# MSPM0G110X register map
Vendor: Texas Instruments; File version: This preliminary header file does not have a version number - build date: 2023-02-21 16:25:48
CPU: CM0 r0p1, little endian, MPU, no FPU, 3 interrupt priority bits
Registers are 32-bit, read-write, reset 0x0 unless marked. A register's access mark holds for its fields unless they carry their own. Offsets are from the block's base; [hi:lo] are bit positions; {n}, {i} and the like mark numbered series; <NAME> marks a mode.

## I2C0 (part 1 of 2) — PERIPHERALREGION
Base 0x400F0000
Same registers: I2C1 0x400F2000
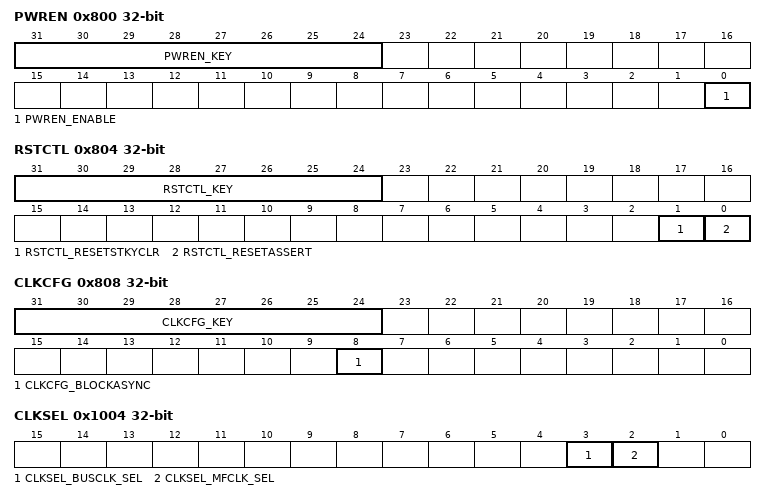
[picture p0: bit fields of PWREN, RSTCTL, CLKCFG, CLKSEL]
0x800 PWREN — Power enable
  [31:24] PWREN_KEY wo — KEY to allow Power State Change
    38=PWREN_KEY_UNLOCK_W (_TO_UNLOCK_W_)
  [0] PWREN_ENABLE — Enable the power
    0=PWREN_ENABLE_DISABLE (DISABLE); 1=PWREN_ENABLE_ENABLE (ENABLE)
0x804 RSTCTL wo — Reset Control
  [31:24] RSTCTL_KEY — Unlock key
    177=RSTCTL_KEY_UNLOCK_W (_TO_UNLOCK_W_)
  [1] RSTCTL_RESETSTKYCLR — Clear the RESETSTKY bit in the STAT register
    0=RSTCTL_RESETSTKYCLR_NOP (NOP); 1=RSTCTL_RESETSTKYCLR_CLR (CLR)
  [0] RSTCTL_RESETASSERT — Assert reset to the peripheral
    0=RSTCTL_RESETASSERT_NOP (NOP); 1=RSTCTL_RESETASSERT_ASSERT (ASSERT)
0x808 CLKCFG — Peripheral Clock Configuration Register
  [31:24] CLKCFG_KEY wo — KEY to Allow State Change -- 0xA9
    169=CLKCFG_KEY_UNLOCK (_UNLOCK_W_)
  [8] CLKCFG_BLOCKASYNC — Async Clock Request is blocked from starting SYSOSC or forcing bus clock to 32MHz
    0=CLKCFG_BLOCKASYNC_DISABLE (DISABLE); 1=CLKCFG_BLOCKASYNC_ENABLE (ENABLE)
0x814 STAT ro — Status Register
  [16] STAT_RESETSTKY — This bit indicates, if the peripheral was reset, since this bit was cleared by RESETSTKYCLR in the RSTCTL register
    0=STAT_RESETSTKY_NORES (NORES); 1=STAT_RESETSTKY_RESET (RESET)
0x1000 CLKDIV — Clock Divider
  [2:0] CLKDIV_RATIO — Selects divide ratio of module clock
    {v}=CLKDIV_RATIO_DIV_BY_{v+1} (DIV_BY_{v+1}) (v=0..7)
0x1004 CLKSEL — Clock Select for Ultra Low Power peripherals
  [3] CLKSEL_BUSCLK_SEL — Selects BUSCLK as clock source if enabled
    0=CLKSEL_BUSCLK_SEL_DISABLE (DISABLE); 1=CLKSEL_BUSCLK_SEL_ENABLE (ENABLE)
  [2] CLKSEL_MFCLK_SEL — Selects MFCLK as clock source if enabled
    0=CLKSEL_MFCLK_SEL_DISABLE (DISABLE); 1=CLKSEL_MFCLK_SEL_ENABLE (ENABLE)
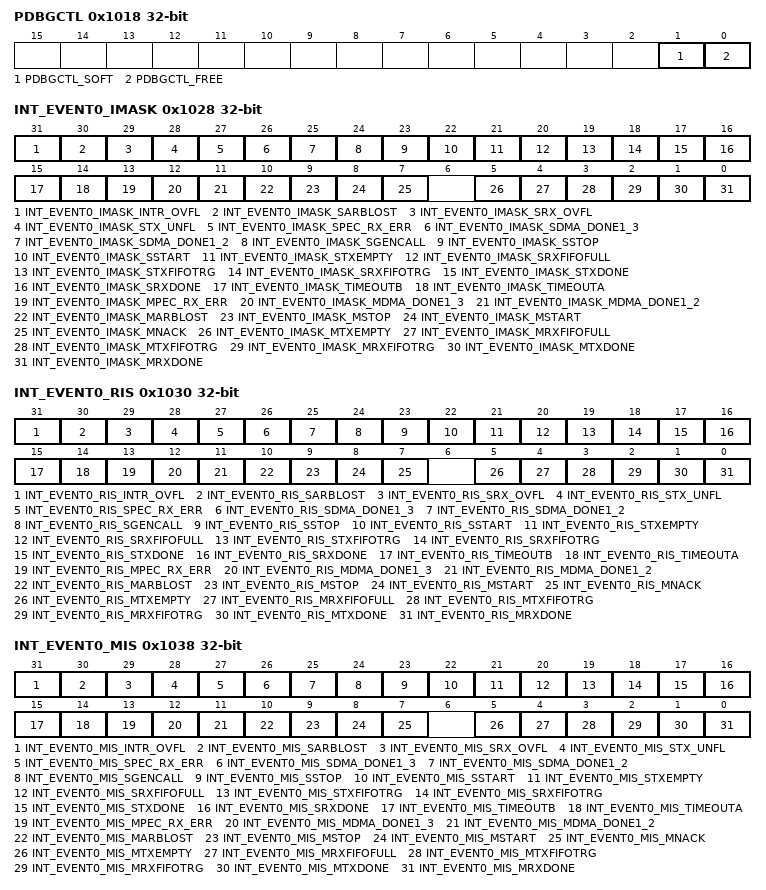
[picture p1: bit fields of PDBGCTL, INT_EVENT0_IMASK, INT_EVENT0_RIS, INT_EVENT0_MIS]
0x1018 PDBGCTL — Peripheral Debug Control
  [1] PDBGCTL_SOFT — Soft halt boundary control. This function is only available, if [FREE] is set to 'STOP'
    0=PDBGCTL_SOFT_IMMEDIATE (IMMEDIATE); 1=PDBGCTL_SOFT_DELAYED (DELAYED)
  [0] PDBGCTL_FREE — Free run control
    0=PDBGCTL_FREE_STOP (STOP); 1=PDBGCTL_FREE_RUN (RUN)
0x1020 INT_EVENT0_IIDX ro — Interrupt index
  [7:0] INT_EVENT0_IIDX_STAT — I2C Module Interrupt Vector Value. This register provides the highes priority interrupt index. A read clears the corresponding interrupt flag in RIS and MISC. 15h-1Fh = Reserved
    0=INT_EVENT0_IIDX_STAT_NO_INTR (NO_INTR); 1=INT_EVENT0_IIDX_STAT_MRXDONEFG (MRXDONEFG); 2=INT_EVENT0_IIDX_STAT_MTXDONEFG (MTXDONEFG); 3=INT_EVENT0_IIDX_STAT_MRXFIFOTRG (MRXFIFOTRG); 4=INT_EVENT0_IIDX_STAT_MTXFIFOTRG (MTXFIFOTRG); 5=INT_EVENT0_IIDX_STAT_MRXFIFOFULL (MRXFIFOFULL); 6=INT_EVENT0_IIDX_STAT_MTX_EMPTY (MTX_EMPTY); 8=INT_EVENT0_IIDX_STAT_MNACKFG (MNACKFG); 9=INT_EVENT0_IIDX_STAT_MSTARTFG (MSTARTFG); 10=INT_EVENT0_IIDX_STAT_MSTOPFG (MSTOPFG); 11=INT_EVENT0_IIDX_STAT_MARBLOSTFG (MARBLOSTFG); 12=INT_EVENT0_IIDX_STAT_MDMA_DONE1_CH2 (MDMA_DONE1_CH2); 13=INT_EVENT0_IIDX_STAT_MDMA_DONE1_CH3 (MDMA_DONE1_CH3); 14=INT_EVENT0_IIDX_STAT_MPEC_RX_ERR (MPEC_RX_ERR); 15=INT_EVENT0_IIDX_STAT_TIMEOUTA (TIMEOUTA); 16=INT_EVENT0_IIDX_STAT_TIMEOUTB (TIMEOUTB); 17=INT_EVENT0_IIDX_STAT_SRXDONEFG (SRXDONEFG); 18=INT_EVENT0_IIDX_STAT_STXDONEFG (STXDONEFG); 19=INT_EVENT0_IIDX_STAT_SRXFIFOTRG (SRXFIFOTRG); 20=INT_EVENT0_IIDX_STAT_STXFIFOTRG (STXFIFOTRG); 21=INT_EVENT0_IIDX_STAT_SRXFIFOFULL (SRXFIFOFULL); 22=INT_EVENT0_IIDX_STAT_STXEMPTY (STXEMPTY); 23=INT_EVENT0_IIDX_STAT_SSTARTFG (SSTARTFG); 24=INT_EVENT0_IIDX_STAT_SSTOPFG (SSTOPFG); 25=INT_EVENT0_IIDX_STAT_SGENCALL (SGENCALL); 26=INT_EVENT0_IIDX_STAT_SDMA_DONE1_CH2 (SDMA_DONE1_CH2); 27=INT_EVENT0_IIDX_STAT_SDMA_DONE1_CH3 (SDMA_DONE1_CH3); 28=INT_EVENT0_IIDX_STAT_SPEC_RX_ERR (SPEC_RX_ERR); 29=INT_EVENT0_IIDX_STAT_STX_UNFL (STX_UNFL); 30=INT_EVENT0_IIDX_STAT_SRX_OVFL (SRX_OVFL); 31=INT_EVENT0_IIDX_STAT_SARBLOST (SARBLOST); 32=INT_EVENT0_IIDX_STAT_INTR_OVFL (INTR_OVFL)
0x1028 INT_EVENT0_IMASK — Interrupt mask
  [31] INT_EVENT0_IMASK_INTR_OVFL — Interrupt Overflow Interrupt Mask
    0=INT_EVENT0_IMASK_INTR_OVFL_CLR (CLR); 1=INT_EVENT0_IMASK_INTR_OVFL_SET (SET)
  [30] INT_EVENT0_IMASK_SARBLOST — Slave Arbitration Lost
    0=INT_EVENT0_IMASK_SARBLOST_CLR (CLR); 1=INT_EVENT0_IMASK_SARBLOST_SET (SET)
  [29] INT_EVENT0_IMASK_SRX_OVFL — Slave RX FIFO overflow
    0=INT_EVENT0_IMASK_SRX_OVFL_CLR (CLR); 1=INT_EVENT0_IMASK_SRX_OVFL_SET (SET)
  [28] INT_EVENT0_IMASK_STX_UNFL — Slave TX FIFO underflow
    0=INT_EVENT0_IMASK_STX_UNFL_CLR (CLR); 1=INT_EVENT0_IMASK_STX_UNFL_SET (SET)
  [27] INT_EVENT0_IMASK_SPEC_RX_ERR — Slave RX Pec Error Interrupt
    0=INT_EVENT0_IMASK_SPEC_RX_ERR_CLR (CLR); 1=INT_EVENT0_IMASK_SPEC_RX_ERR_SET (SET)
  [26] INT_EVENT0_IMASK_SDMA_DONE1_3 — Slave DMA Done 1 on Event Channel 3
    0=INT_EVENT0_IMASK_SDMA_DONE1_3_CLR (CLR); 1=INT_EVENT0_IMASK_SDMA_DONE1_3_SET (SET)
  [25] INT_EVENT0_IMASK_SDMA_DONE1_2 — Slave DMA Done 1 on Event Channel 2
    0=INT_EVENT0_IMASK_SDMA_DONE1_2_CLR (CLR); 1=INT_EVENT0_IMASK_SDMA_DONE1_2_SET (SET)
  [24] INT_EVENT0_IMASK_SGENCALL — General Call Interrupt
    0=INT_EVENT0_IMASK_SGENCALL_CLR (CLR); 1=INT_EVENT0_IMASK_SGENCALL_SET (SET)
  [23] INT_EVENT0_IMASK_SSTOP — Stop Condition Interrupt
    0=INT_EVENT0_IMASK_SSTOP_CLR (CLR); 1=INT_EVENT0_IMASK_SSTOP_SET (SET)
  [22] INT_EVENT0_IMASK_SSTART — Start Condition Interrupt
    0=INT_EVENT0_IMASK_SSTART_CLR (CLR); 1=INT_EVENT0_IMASK_SSTART_SET (SET)
  [21] INT_EVENT0_IMASK_STXEMPTY — Slave Transmit FIFO Empty interrupt mask. This interrupt is set if all data in the Transmit FIFO have been shifted out and the transmit goes into idle mode.
    0=INT_EVENT0_IMASK_STXEMPTY_CLR (CLR); 1=INT_EVENT0_IMASK_STXEMPTY_SET (SET)
  [20] INT_EVENT0_IMASK_SRXFIFOFULL — RXFIFO full event. This interrupt is set if an Slave RX FIFO is full.
    0=INT_EVENT0_IMASK_SRXFIFOFULL_CLR (CLR); 1=INT_EVENT0_IMASK_SRXFIFOFULL_SET (SET)
  [19] INT_EVENT0_IMASK_STXFIFOTRG — Slave Transmit FIFO Trigger
    0=INT_EVENT0_IMASK_STXFIFOTRG_CLR (CLR); 1=INT_EVENT0_IMASK_STXFIFOTRG_SET (SET)
  [18] INT_EVENT0_IMASK_SRXFIFOTRG — Slave Receive FIFO Trigger
    0=INT_EVENT0_IMASK_SRXFIFOTRG_CLR (CLR); 1=INT_EVENT0_IMASK_SRXFIFOTRG_SET (SET)
  [17] INT_EVENT0_IMASK_STXDONE — Slave Transmit Transaction completed Interrupt
    0=INT_EVENT0_IMASK_STXDONE_CLR (CLR); 1=INT_EVENT0_IMASK_STXDONE_SET (SET)
  [16] INT_EVENT0_IMASK_SRXDONE — Slave Receive Data Interrupt Signals that a byte has been received
    0=INT_EVENT0_IMASK_SRXDONE_CLR (CLR); 1=INT_EVENT0_IMASK_SRXDONE_SET (SET)
  [15] INT_EVENT0_IMASK_TIMEOUTB — Timeout B Interrupt
    0=INT_EVENT0_IMASK_TIMEOUTB_CLR (CLR); 1=INT_EVENT0_IMASK_TIMEOUTB_SET (SET)
  [14] INT_EVENT0_IMASK_TIMEOUTA — Timeout A Interrupt
    0=INT_EVENT0_IMASK_TIMEOUTA_CLR (CLR); 1=INT_EVENT0_IMASK_TIMEOUTA_SET (SET)
  [13] INT_EVENT0_IMASK_MPEC_RX_ERR — Master RX Pec Error Interrupt
    0=INT_EVENT0_IMASK_MPEC_RX_ERR_CLR (CLR); 1=INT_EVENT0_IMASK_MPEC_RX_ERR_SET (SET)
  [12] INT_EVENT0_IMASK_MDMA_DONE1_3 — DMA Done 1 on Event Channel 3
    0=INT_EVENT0_IMASK_MDMA_DONE1_3_CLR (CLR); 1=INT_EVENT0_IMASK_MDMA_DONE1_3_SET (SET)
  [11] INT_EVENT0_IMASK_MDMA_DONE1_2 — DMA Done 1 on Event Channel 2
    0=INT_EVENT0_IMASK_MDMA_DONE1_2_CLR (CLR); 1=INT_EVENT0_IMASK_MDMA_DONE1_2_SET (SET)
  [10] INT_EVENT0_IMASK_MARBLOST — Arbitration Lost Interrupt
    0=INT_EVENT0_IMASK_MARBLOST_CLR (CLR); 1=INT_EVENT0_IMASK_MARBLOST_SET (SET)
  [9] INT_EVENT0_IMASK_MSTOP — STOP Detection Interrupt
    0=INT_EVENT0_IMASK_MSTOP_CLR (CLR); 1=INT_EVENT0_IMASK_MSTOP_SET (SET)
  [8] INT_EVENT0_IMASK_MSTART — START Detection Interrupt
    0=INT_EVENT0_IMASK_MSTART_CLR (CLR); 1=INT_EVENT0_IMASK_MSTART_SET (SET)
  [7] INT_EVENT0_IMASK_MNACK — Address/Data NACK Interrupt
    0=INT_EVENT0_IMASK_MNACK_CLR (CLR); 1=INT_EVENT0_IMASK_MNACK_SET (SET)
  [5] INT_EVENT0_IMASK_MTXEMPTY — Transmit FIFO Empty interrupt mask. This interrupt is set if all data in the Transmit FIFO have been shifted out and the transmit goes into idle mode.
    0=INT_EVENT0_IMASK_MTXEMPTY_CLR (CLR); 1=INT_EVENT0_IMASK_MTXEMPTY_SET (SET)
  [4] INT_EVENT0_IMASK_MRXFIFOFULL — RXFIFO full event. This interrupt is set if an RX FIFO is full.
    0=INT_EVENT0_IMASK_MRXFIFOFULL_CLR (CLR); 1=INT_EVENT0_IMASK_MRXFIFOFULL_SET (SET)
  [3] INT_EVENT0_IMASK_MTXFIFOTRG — Master Transmit FIFO Trigger Trigger when Transmit FIFO contains <= defined bytes
    0=INT_EVENT0_IMASK_MTXFIFOTRG_CLR (CLR); 1=INT_EVENT0_IMASK_MTXFIFOTRG_SET (SET)
  [2] INT_EVENT0_IMASK_MRXFIFOTRG — Master Receive FIFO Trigger Trigger when RX FIFO contains >= defined bytes
    0=INT_EVENT0_IMASK_MRXFIFOTRG_CLR (CLR); 1=INT_EVENT0_IMASK_MRXFIFOTRG_SET (SET)
  [1] INT_EVENT0_IMASK_MTXDONE — Master Transmit Transaction completed Interrupt
    0=INT_EVENT0_IMASK_MTXDONE_CLR (CLR); 1=INT_EVENT0_IMASK_MTXDONE_SET (SET)
  [0] INT_EVENT0_IMASK_MRXDONE — Master Receive Transaction completed Interrupt
    0=INT_EVENT0_IMASK_MRXDONE_CLR (CLR); 1=INT_EVENT0_IMASK_MRXDONE_SET (SET)
0x1030 INT_EVENT0_RIS ro — Raw interrupt status
  [31] INT_EVENT0_RIS_INTR_OVFL — Interrupt overflow interrupt It is set when SSTART or SSTOP interrupts overflow i.e. occur twice without being serviced
    0=INT_EVENT0_RIS_INTR_OVFL_CLR (CLR); 1=INT_EVENT0_RIS_INTR_OVFL_SET (SET)
  [30] INT_EVENT0_RIS_SARBLOST — Slave Arbitration Lost
    0=INT_EVENT0_RIS_SARBLOST_CLR (CLR); 1=INT_EVENT0_RIS_SARBLOST_SET (SET)
  [29] INT_EVENT0_RIS_SRX_OVFL — Slave RX FIFO overflow
    0=INT_EVENT0_RIS_SRX_OVFL_CLR (CLR); 1=INT_EVENT0_RIS_SRX_OVFL_SET (SET)
  [28] INT_EVENT0_RIS_STX_UNFL — Slave TX FIFO underflow
    0=INT_EVENT0_RIS_STX_UNFL_CLR (CLR); 1=INT_EVENT0_RIS_STX_UNFL_SET (SET)
  [27] INT_EVENT0_RIS_SPEC_RX_ERR — Slave RX Pec Error Interrupt
    0=INT_EVENT0_RIS_SPEC_RX_ERR_CLR (CLR); 1=INT_EVENT0_RIS_SPEC_RX_ERR_SET (SET)
  [26] INT_EVENT0_RIS_SDMA_DONE1_3 — DMA Done 1 on Event Channel 3
    0=INT_EVENT0_RIS_SDMA_DONE1_3_CLR (CLR); 1=INT_EVENT0_RIS_SDMA_DONE1_3_SET (SET)
  [25] INT_EVENT0_RIS_SDMA_DONE1_2 — DMA Done 1 on Event Channel 2
    0=INT_EVENT0_RIS_SDMA_DONE1_2_CLR (CLR); 1=INT_EVENT0_RIS_SDMA_DONE1_2_SET (SET)
  [24] INT_EVENT0_RIS_SGENCALL — General Call Interrupt
    0=INT_EVENT0_RIS_SGENCALL_CLR (CLR); 1=INT_EVENT0_RIS_SGENCALL_SET (SET)
  [23] INT_EVENT0_RIS_SSTOP — Stop Condition Interrupt
    0=INT_EVENT0_RIS_SSTOP_CLR (CLR); 1=INT_EVENT0_RIS_SSTOP_SET (SET)
  [22] INT_EVENT0_RIS_SSTART — Start Condition Interrupt
    0=INT_EVENT0_RIS_SSTART_CLR (CLR); 1=INT_EVENT0_RIS_SSTART_SET (SET)
  [21] INT_EVENT0_RIS_STXEMPTY — Transmit FIFO Empty interrupt mask. This interrupt is set if all data in the Transmit FIFO have been shifted out and the transmit goes into idle mode.
    0=INT_EVENT0_RIS_STXEMPTY_CLR (CLR); 1=INT_EVENT0_RIS_STXEMPTY_SET (SET)
  [20] INT_EVENT0_RIS_SRXFIFOFULL — RXFIFO full event. This interrupt is set if an RX FIFO is full.
    0=INT_EVENT0_RIS_SRXFIFOFULL_CLR (CLR); 1=INT_EVENT0_RIS_SRXFIFOFULL_SET (SET)
  [19] INT_EVENT0_RIS_STXFIFOTRG — Slave Transmit FIFO Trigger
    0=INT_EVENT0_RIS_STXFIFOTRG_CLR (CLR); 1=INT_EVENT0_RIS_STXFIFOTRG_SET (SET)
  [18] INT_EVENT0_RIS_SRXFIFOTRG — Slave Receive FIFO Trigger
    0=INT_EVENT0_RIS_SRXFIFOTRG_CLR (CLR); 1=INT_EVENT0_RIS_SRXFIFOTRG_SET (SET)
  [17] INT_EVENT0_RIS_STXDONE — Slave Transmit Transaction completed Interrupt
    0=INT_EVENT0_RIS_STXDONE_CLR (CLR); 1=INT_EVENT0_RIS_STXDONE_SET (SET)
  [16] INT_EVENT0_RIS_SRXDONE — Slave Receive Data Interrupt Signals that a byte has been received
    0=INT_EVENT0_RIS_SRXDONE_CLR (CLR); 1=INT_EVENT0_RIS_SRXDONE_SET (SET)
  [15] INT_EVENT0_RIS_TIMEOUTB — Timeout B Interrupt
    0=INT_EVENT0_RIS_TIMEOUTB_CLR (CLR); 1=INT_EVENT0_RIS_TIMEOUTB_SET (SET)
  [14] INT_EVENT0_RIS_TIMEOUTA — Timeout A Interrupt
    0=INT_EVENT0_RIS_TIMEOUTA_CLR (CLR); 1=INT_EVENT0_RIS_TIMEOUTA_SET (SET)
  [13] INT_EVENT0_RIS_MPEC_RX_ERR — Master RX Pec Error Interrupt
    0=INT_EVENT0_RIS_MPEC_RX_ERR_CLR (CLR); 1=INT_EVENT0_RIS_MPEC_RX_ERR_SET (SET)
  [12] INT_EVENT0_RIS_MDMA_DONE1_3 — DMA Done 1 on Event Channel 3
    0=INT_EVENT0_RIS_MDMA_DONE1_3_CLR (CLR); 1=INT_EVENT0_RIS_MDMA_DONE1_3_SET (SET)
  [11] INT_EVENT0_RIS_MDMA_DONE1_2 — DMA Done 1 on Event Channel 2
    0=INT_EVENT0_RIS_MDMA_DONE1_2_CLR (CLR); 1=INT_EVENT0_RIS_MDMA_DONE1_2_SET (SET)
  [10] INT_EVENT0_RIS_MARBLOST — Arbitration Lost Interrupt
    0=INT_EVENT0_RIS_MARBLOST_CLR (CLR); 1=INT_EVENT0_RIS_MARBLOST_SET (SET)
  [9] INT_EVENT0_RIS_MSTOP — STOP Detection Interrupt
    0=INT_EVENT0_RIS_MSTOP_CLR (CLR); 1=INT_EVENT0_RIS_MSTOP_SET (SET)
  [8] INT_EVENT0_RIS_MSTART — START Detection Interrupt
    0=INT_EVENT0_RIS_MSTART_CLR (CLR); 1=INT_EVENT0_RIS_MSTART_SET (SET)
  [7] INT_EVENT0_RIS_MNACK — Address/Data NACK Interrupt
    0=INT_EVENT0_RIS_MNACK_CLR (CLR); 1=INT_EVENT0_RIS_MNACK_SET (SET)
  [5] INT_EVENT0_RIS_MTXEMPTY — Transmit FIFO Empty interrupt mask. This interrupt is set if all data in the Transmit FIFO have been shifted out and the transmit goes into idle mode.
    0=INT_EVENT0_RIS_MTXEMPTY_CLR (CLR); 1=INT_EVENT0_RIS_MTXEMPTY_SET (SET)
  [4] INT_EVENT0_RIS_MRXFIFOFULL — RXFIFO full event. This interrupt is set if an RX FIFO is full.
    0=INT_EVENT0_RIS_MRXFIFOFULL_CLR (CLR); 1=INT_EVENT0_RIS_MRXFIFOFULL_SET (SET)
  [3] INT_EVENT0_RIS_MTXFIFOTRG — Master Transmit FIFO Trigger Trigger when Transmit FIFO contains <= defined bytes
    0=INT_EVENT0_RIS_MTXFIFOTRG_CLR (CLR); 1=INT_EVENT0_RIS_MTXFIFOTRG_SET (SET)
  [2] INT_EVENT0_RIS_MRXFIFOTRG — Master Receive FIFO Trigger Trigger when RX FIFO contains >= defined bytes
    0=INT_EVENT0_RIS_MRXFIFOTRG_CLR (CLR); 1=INT_EVENT0_RIS_MRXFIFOTRG_SET (SET)
  [1] INT_EVENT0_RIS_MTXDONE — Master Transmit Transaction completed Interrupt
    0=INT_EVENT0_RIS_MTXDONE_CLR (CLR); 1=INT_EVENT0_RIS_MTXDONE_SET (SET)
  [0] INT_EVENT0_RIS_MRXDONE — Master Receive Transaction completed Interrupt
    0=INT_EVENT0_RIS_MRXDONE_CLR (CLR); 1=INT_EVENT0_RIS_MRXDONE_SET (SET)
0x1038 INT_EVENT0_MIS ro — Masked interrupt status
  [31] INT_EVENT0_MIS_INTR_OVFL — Interrupt overflow
    0=INT_EVENT0_MIS_INTR_OVFL_CLR (CLR); 1=INT_EVENT0_MIS_INTR_OVFL_SET (SET)
  [30] INT_EVENT0_MIS_SARBLOST — Slave Arbitration Lost
    0=INT_EVENT0_MIS_SARBLOST_CLR (CLR); 1=INT_EVENT0_MIS_SARBLOST_SET (SET)
  [29] INT_EVENT0_MIS_SRX_OVFL — Slave RX FIFO overflow
    0=INT_EVENT0_MIS_SRX_OVFL_CLR (CLR); 1=INT_EVENT0_MIS_SRX_OVFL_SET (SET)
  [28] INT_EVENT0_MIS_STX_UNFL — Slave TX FIFO underflow
    0=INT_EVENT0_MIS_STX_UNFL_CLR (CLR); 1=INT_EVENT0_MIS_STX_UNFL_SET (SET)
  [27] INT_EVENT0_MIS_SPEC_RX_ERR — Slave RX Pec Error Interrupt
    0=INT_EVENT0_MIS_SPEC_RX_ERR_CLR (CLR); 1=INT_EVENT0_MIS_SPEC_RX_ERR_SET (SET)
  [26] INT_EVENT0_MIS_SDMA_DONE1_3 — DMA Done 1 on Event Channel 3
    0=INT_EVENT0_MIS_SDMA_DONE1_3_CLR (CLR); 1=INT_EVENT0_MIS_SDMA_DONE1_3_SET (SET)
  [25] INT_EVENT0_MIS_SDMA_DONE1_2 — DMA Done 1 on Event Channel 2
    0=INT_EVENT0_MIS_SDMA_DONE1_2_CLR (CLR); 1=INT_EVENT0_MIS_SDMA_DONE1_2_SET (SET)
  [24] INT_EVENT0_MIS_SGENCALL — General Call Interrupt
    0=INT_EVENT0_MIS_SGENCALL_CLR (CLR); 1=INT_EVENT0_MIS_SGENCALL_SET (SET)
  [23] INT_EVENT0_MIS_SSTOP — Slave STOP Detection Interrupt
    0=INT_EVENT0_MIS_SSTOP_CLR (CLR); 1=INT_EVENT0_MIS_SSTOP_SET (SET)
  [22] INT_EVENT0_MIS_SSTART — Slave START Detection Interrupt
    0=INT_EVENT0_MIS_SSTART_CLR (CLR); 1=INT_EVENT0_MIS_SSTART_SET (SET)
  [21] INT_EVENT0_MIS_STXEMPTY — Transmit FIFO Empty interrupt mask. This interrupt is set if all data in the Transmit FIFO have been shifted out and the transmit goes into idle mode.
    0=INT_EVENT0_MIS_STXEMPTY_CLR (CLR); 1=INT_EVENT0_MIS_STXEMPTY_SET (SET)
  [20] INT_EVENT0_MIS_SRXFIFOFULL — RXFIFO full event. This interrupt is set if an RX FIFO is full.
    0=INT_EVENT0_MIS_SRXFIFOFULL_CLR (CLR); 1=INT_EVENT0_MIS_SRXFIFOFULL_SET (SET)
  [19] INT_EVENT0_MIS_STXFIFOTRG — Slave Transmit FIFO Trigger
    0=INT_EVENT0_MIS_STXFIFOTRG_CLR (CLR); 1=INT_EVENT0_MIS_STXFIFOTRG_SET (SET)
  [18] INT_EVENT0_MIS_SRXFIFOTRG — Slave Receive FIFO Trigger
    0=INT_EVENT0_MIS_SRXFIFOTRG_CLR (CLR); 1=INT_EVENT0_MIS_SRXFIFOTRG_SET (SET)
  [17] INT_EVENT0_MIS_STXDONE — Slave Transmit Transaction completed Interrupt
    0=INT_EVENT0_MIS_STXDONE_CLR (CLR); 1=INT_EVENT0_MIS_STXDONE_SET (SET)
  [16] INT_EVENT0_MIS_SRXDONE — Slave Receive Data Interrupt Signals that a byte has been received
    0=INT_EVENT0_MIS_SRXDONE_CLR (CLR); 1=INT_EVENT0_MIS_SRXDONE_SET (SET)
  [15] INT_EVENT0_MIS_TIMEOUTB — Timeout B Interrupt
    0=INT_EVENT0_MIS_TIMEOUTB_CLR (CLR); 1=INT_EVENT0_MIS_TIMEOUTB_SET (SET)
  [14] INT_EVENT0_MIS_TIMEOUTA — Timeout A Interrupt
    0=INT_EVENT0_MIS_TIMEOUTA_CLR (CLR); 1=INT_EVENT0_MIS_TIMEOUTA_SET (SET)
  [13] INT_EVENT0_MIS_MPEC_RX_ERR — Master RX Pec Error Interrupt
    0=INT_EVENT0_MIS_MPEC_RX_ERR_CLR (CLR); 1=INT_EVENT0_MIS_MPEC_RX_ERR_SET (SET)
  [12] INT_EVENT0_MIS_MDMA_DONE1_3 — DMA Done 1 on Event Channel 3
    0=INT_EVENT0_MIS_MDMA_DONE1_3_CLR (CLR); 1=INT_EVENT0_MIS_MDMA_DONE1_3_SET (SET)
  [11] INT_EVENT0_MIS_MDMA_DONE1_2 — DMA Done 1 on Event Channel 2
    0=INT_EVENT0_MIS_MDMA_DONE1_2_CLR (CLR); 1=INT_EVENT0_MIS_MDMA_DONE1_2_SET (SET)
  [10] INT_EVENT0_MIS_MARBLOST — Arbitration Lost Interrupt
    0=INT_EVENT0_MIS_MARBLOST_CLR (CLR); 1=INT_EVENT0_MIS_MARBLOST_SET (SET)
  [9] INT_EVENT0_MIS_MSTOP — STOP Detection Interrupt
    0=INT_EVENT0_MIS_MSTOP_CLR (CLR); 1=INT_EVENT0_MIS_MSTOP_SET (SET)
  [8] INT_EVENT0_MIS_MSTART — START Detection Interrupt
    0=INT_EVENT0_MIS_MSTART_CLR (CLR); 1=INT_EVENT0_MIS_MSTART_SET (SET)
  [7] INT_EVENT0_MIS_MNACK — Address/Data NACK Interrupt
    0=INT_EVENT0_MIS_MNACK_CLR (CLR); 1=INT_EVENT0_MIS_MNACK_SET (SET)
  [5] INT_EVENT0_MIS_MTXEMPTY — Transmit FIFO Empty interrupt mask. This interrupt is set if all data in the Transmit FIFO have been shifted out and the transmit goes into idle mode.
    0=INT_EVENT0_MIS_MTXEMPTY_CLR (CLR); 1=INT_EVENT0_MIS_MTXEMPTY_SET (SET)
  [4] INT_EVENT0_MIS_MRXFIFOFULL — RXFIFO full event. This interrupt is set if the RX FIFO is full.
    0=INT_EVENT0_MIS_MRXFIFOFULL_CLR (CLR); 1=INT_EVENT0_MIS_MRXFIFOFULL_SET (SET)
  [3] INT_EVENT0_MIS_MTXFIFOTRG — Master Transmit FIFO Trigger Trigger when Transmit FIFO contains <= defined bytes
    0=INT_EVENT0_MIS_MTXFIFOTRG_CLR (CLR); 1=INT_EVENT0_MIS_MTXFIFOTRG_SET (SET)
  [2] INT_EVENT0_MIS_MRXFIFOTRG — Master Receive FIFO Trigger Trigger when RX FIFO contains >= defined bytes
    0=INT_EVENT0_MIS_MRXFIFOTRG_CLR (CLR); 1=INT_EVENT0_MIS_MRXFIFOTRG_SET (SET)
  [1] INT_EVENT0_MIS_MTXDONE — Master Transmit Transaction completed Interrupt
    0=INT_EVENT0_MIS_MTXDONE_CLR (CLR); 1=INT_EVENT0_MIS_MTXDONE_SET (SET)
  [0] INT_EVENT0_MIS_MRXDONE — Master Receive Data Interrupt
    0=INT_EVENT0_MIS_MRXDONE_CLR (CLR); 1=INT_EVENT0_MIS_MRXDONE_SET (SET)
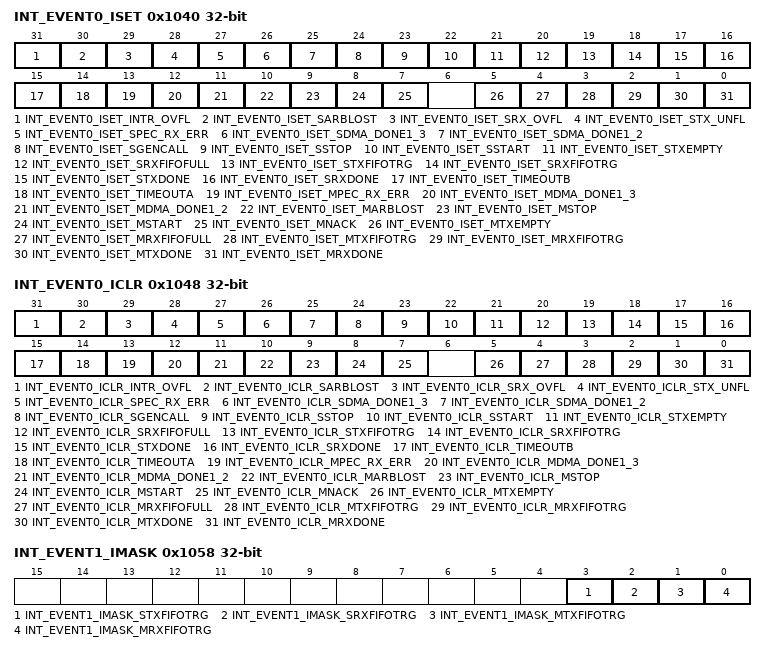
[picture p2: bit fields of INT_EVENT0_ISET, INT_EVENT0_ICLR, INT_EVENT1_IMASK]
0x1040 INT_EVENT0_ISET wo — Interrupt set
  [31] INT_EVENT0_ISET_INTR_OVFL — Interrupt overflow
    0=INT_EVENT0_ISET_INTR_OVFL_NO_EFFECT (NO_EFFECT); 1=INT_EVENT0_ISET_INTR_OVFL_SET (SET)
  [30] INT_EVENT0_ISET_SARBLOST — Slave Arbitration Lost
    0=INT_EVENT0_ISET_SARBLOST_NO_EFFECT (NO_EFFECT); 1=INT_EVENT0_ISET_SARBLOST_SET (SET)
  [29] INT_EVENT0_ISET_SRX_OVFL — Slave RX FIFO overflow
    0=INT_EVENT0_ISET_SRX_OVFL_NO_EFFECT (NO_EFFECT); 1=INT_EVENT0_ISET_SRX_OVFL_SET (SET)
  [28] INT_EVENT0_ISET_STX_UNFL — Slave TX FIFO underflow
    0=INT_EVENT0_ISET_STX_UNFL_NO_EFFECT (NO_EFFECT); 1=INT_EVENT0_ISET_STX_UNFL_SET (SET)
  [27] INT_EVENT0_ISET_SPEC_RX_ERR — Slave RX Pec Error Interrupt
    0=INT_EVENT0_ISET_SPEC_RX_ERR_NO_EFFECT (NO_EFFECT); 1=INT_EVENT0_ISET_SPEC_RX_ERR_SET (SET)
  [26] INT_EVENT0_ISET_SDMA_DONE1_3 — DMA Done 1 on Event Channel 3
    0=INT_EVENT0_ISET_SDMA_DONE1_3_NO_EFFECT (NO_EFFECT); 1=INT_EVENT0_ISET_SDMA_DONE1_3_SET (SET)
  [25] INT_EVENT0_ISET_SDMA_DONE1_2 — DMA Done 1 on Event Channel 2
    0=INT_EVENT0_ISET_SDMA_DONE1_2_NO_EFFECT (NO_EFFECT); 1=INT_EVENT0_ISET_SDMA_DONE1_2_SET (SET)
  [24] INT_EVENT0_ISET_SGENCALL — General Call Interrupt
    0=INT_EVENT0_ISET_SGENCALL_NO_EFFECT (NO_EFFECT); 1=INT_EVENT0_ISET_SGENCALL_SET (SET)
  [23] INT_EVENT0_ISET_SSTOP — Stop Condition Interrupt
    0=INT_EVENT0_ISET_SSTOP_NO_EFFECT (NO_EFFECT); 1=INT_EVENT0_ISET_SSTOP_SET (SET)
  [22] INT_EVENT0_ISET_SSTART — Start Condition Interrupt
    0=INT_EVENT0_ISET_SSTART_NO_EFFECT (NO_EFFECT); 1=INT_EVENT0_ISET_SSTART_SET (SET)
  [21] INT_EVENT0_ISET_STXEMPTY — Transmit FIFO Empty interrupt mask. This interrupt is set if all data in the Transmit FIFO have been shifted out and the transmit goes into idle mode.
    0=INT_EVENT0_ISET_STXEMPTY_NO_EFFECT (NO_EFFECT); 1=INT_EVENT0_ISET_STXEMPTY_SET (SET)
  [20] INT_EVENT0_ISET_SRXFIFOFULL — RXFIFO full event. This interrupt is set if an RX FIFO is full.
    0=INT_EVENT0_ISET_SRXFIFOFULL_NO_EFFECT (NO_EFFECT); 1=INT_EVENT0_ISET_SRXFIFOFULL_SET (SET)
  [19] INT_EVENT0_ISET_STXFIFOTRG — Slave Transmit FIFO Trigger
    0=INT_EVENT0_ISET_STXFIFOTRG_NO_EFFECT (NO_EFFECT); 1=INT_EVENT0_ISET_STXFIFOTRG_SET (SET)
  [18] INT_EVENT0_ISET_SRXFIFOTRG — Slave Receive FIFO Trigger
    0=INT_EVENT0_ISET_SRXFIFOTRG_NO_EFFECT (NO_EFFECT); 1=INT_EVENT0_ISET_SRXFIFOTRG_SET (SET)
  [17] INT_EVENT0_ISET_STXDONE — Slave Transmit Transaction completed Interrupt
    0=INT_EVENT0_ISET_STXDONE_NO_EFFECT (NO_EFFECT); 1=INT_EVENT0_ISET_STXDONE_SET (SET)
  [16] INT_EVENT0_ISET_SRXDONE — Slave Receive Data Interrupt Signals that a byte has been received
    0=INT_EVENT0_ISET_SRXDONE_NO_EFFECT (NO_EFFECT); 1=INT_EVENT0_ISET_SRXDONE_SET (SET)
  [15] INT_EVENT0_ISET_TIMEOUTB — Timeout B Interrupt
    0=INT_EVENT0_ISET_TIMEOUTB_NO_EFFECT (NO_EFFECT); 1=INT_EVENT0_ISET_TIMEOUTB_SET (SET)
  [14] INT_EVENT0_ISET_TIMEOUTA — Timeout A interrupt
    0=INT_EVENT0_ISET_TIMEOUTA_NO_EFFECT (NO_EFFECT); 1=INT_EVENT0_ISET_TIMEOUTA_SET (SET)
  [13] INT_EVENT0_ISET_MPEC_RX_ERR — Master RX Pec Error Interrupt
    0=INT_EVENT0_ISET_MPEC_RX_ERR_NO_EFFECT (NO_EFFECT); 1=INT_EVENT0_ISET_MPEC_RX_ERR_SET (SET)
  [12] INT_EVENT0_ISET_MDMA_DONE1_3 — DMA Done 1 on Event Channel 3
    0=INT_EVENT0_ISET_MDMA_DONE1_3_NO_EFFECT (NO_EFFECT); 1=INT_EVENT0_ISET_MDMA_DONE1_3_SET (SET)
  [11] INT_EVENT0_ISET_MDMA_DONE1_2 — DMA Done 1 on Event Channel 2
    0=INT_EVENT0_ISET_MDMA_DONE1_2_NO_EFFECT (NO_EFFECT); 1=INT_EVENT0_ISET_MDMA_DONE1_2_SET (SET)
  [10] INT_EVENT0_ISET_MARBLOST — Arbitration Lost Interrupt
    0=INT_EVENT0_ISET_MARBLOST_NO_EFFECT (NO_EFFECT); 1=INT_EVENT0_ISET_MARBLOST_SET (SET)
  [9] INT_EVENT0_ISET_MSTOP — STOP Detection Interrupt
    0=INT_EVENT0_ISET_MSTOP_NO_EFFECT (NO_EFFECT); 1=INT_EVENT0_ISET_MSTOP_SET (SET)
  [8] INT_EVENT0_ISET_MSTART — START Detection Interrupt
    0=INT_EVENT0_ISET_MSTART_NO_EFFECT (NO_EFFECT); 1=INT_EVENT0_ISET_MSTART_SET (SET)
  [7] INT_EVENT0_ISET_MNACK — Address/Data NACK Interrupt
    0=INT_EVENT0_ISET_MNACK_NO_EFFECT (NO_EFFECT); 1=INT_EVENT0_ISET_MNACK_SET (SET)
  [5] INT_EVENT0_ISET_MTXEMPTY — Transmit FIFO Empty interrupt mask. This interrupt is set if all data in the Transmit FIFO have been shifted out and the transmit goes into idle mode.
    0=INT_EVENT0_ISET_MTXEMPTY_NO_EFFECT (NO_EFFECT); 1=INT_EVENT0_ISET_MTXEMPTY_SET (SET)
  [4] INT_EVENT0_ISET_MRXFIFOFULL — RXFIFO full event.
    0=INT_EVENT0_ISET_MRXFIFOFULL_NO_EFFECT (NO_EFFECT); 1=INT_EVENT0_ISET_MRXFIFOFULL_SET (SET)
  [3] INT_EVENT0_ISET_MTXFIFOTRG — Master Transmit FIFO Trigger Trigger when Transmit FIFO contains <= defined bytes
    0=INT_EVENT0_ISET_MTXFIFOTRG_NO_EFFECT (NO_EFFECT); 1=INT_EVENT0_ISET_MTXFIFOTRG_SET (SET)
  [2] INT_EVENT0_ISET_MRXFIFOTRG — Master Receive FIFO Trigger Trigger when RX FIFO contains >= defined bytes
    0=INT_EVENT0_ISET_MRXFIFOTRG_NO_EFFECT (NO_EFFECT); 1=INT_EVENT0_ISET_MRXFIFOTRG_SET (SET)
  [1] INT_EVENT0_ISET_MTXDONE — Master Transmit Transaction completed Interrupt
    0=INT_EVENT0_ISET_MTXDONE_NO_EFFECT (NO_EFFECT); 1=INT_EVENT0_ISET_MTXDONE_SET (SET)
  [0] INT_EVENT0_ISET_MRXDONE — Master Receive Data Interrupt Signals that a byte has been received
    0=INT_EVENT0_ISET_MRXDONE_NO_EFFECT (NO_EFFECT); 1=INT_EVENT0_ISET_MRXDONE_SET (SET)
0x1048 INT_EVENT0_ICLR wo — Interrupt clear
  [31] INT_EVENT0_ICLR_INTR_OVFL — Interrupt overflow
    0=INT_EVENT0_ICLR_INTR_OVFL_NO_EFFECT (NO_EFFECT); 1=INT_EVENT0_ICLR_INTR_OVFL_CLR (CLR)
  [30] INT_EVENT0_ICLR_SARBLOST — Slave Arbitration Lost
    0=INT_EVENT0_ICLR_SARBLOST_NO_EFFECT (NO_EFFECT); 1=INT_EVENT0_ICLR_SARBLOST_CLR (CLR)
  [29] INT_EVENT0_ICLR_SRX_OVFL — Slave RX FIFO overflow
    0=INT_EVENT0_ICLR_SRX_OVFL_NO_EFFECT (NO_EFFECT); 1=INT_EVENT0_ICLR_SRX_OVFL_CLR (CLR)
  [28] INT_EVENT0_ICLR_STX_UNFL — Slave TX FIFO underflow
    0=INT_EVENT0_ICLR_STX_UNFL_NO_EFFECT (NO_EFFECT); 1=INT_EVENT0_ICLR_STX_UNFL_CLR (CLR)
  [27] INT_EVENT0_ICLR_SPEC_RX_ERR — Slave RX Pec Error Interrupt
    0=INT_EVENT0_ICLR_SPEC_RX_ERR_NO_EFFECT (NO_EFFECT); 1=INT_EVENT0_ICLR_SPEC_RX_ERR_CLR (CLR)
  [26] INT_EVENT0_ICLR_SDMA_DONE1_3 — DMA Done 1 on Event Channel 3
    0=INT_EVENT0_ICLR_SDMA_DONE1_3_NO_EFFECT (NO_EFFECT); 1=INT_EVENT0_ICLR_SDMA_DONE1_3_CLR (CLR)
  [25] INT_EVENT0_ICLR_SDMA_DONE1_2 — DMA Done 1 on Event Channel 2
    0=INT_EVENT0_ICLR_SDMA_DONE1_2_NO_EFFECT (NO_EFFECT); 1=INT_EVENT0_ICLR_SDMA_DONE1_2_CLR (CLR)
  [24] INT_EVENT0_ICLR_SGENCALL — General Call Interrupt
    0=INT_EVENT0_ICLR_SGENCALL_NO_EFFECT (NO_EFFECT); 1=INT_EVENT0_ICLR_SGENCALL_CLR (CLR)
  [23] INT_EVENT0_ICLR_SSTOP — Slave STOP Detection Interrupt
    0=INT_EVENT0_ICLR_SSTOP_NO_EFFECT (NO_EFFECT); 1=INT_EVENT0_ICLR_SSTOP_CLR (CLR)
  [22] INT_EVENT0_ICLR_SSTART — Slave START Detection Interrupt
    0=INT_EVENT0_ICLR_SSTART_NO_EFFECT (NO_EFFECT); 1=INT_EVENT0_ICLR_SSTART_CLR (CLR)
  [21] INT_EVENT0_ICLR_STXEMPTY — Transmit FIFO Empty interrupt mask. This interrupt is set if all data in the Transmit FIFO have been shifted out and the transmit goes into idle mode.
    0=INT_EVENT0_ICLR_STXEMPTY_NO_EFFECT (NO_EFFECT); 1=INT_EVENT0_ICLR_STXEMPTY_CLR (CLR)
  [20] INT_EVENT0_ICLR_SRXFIFOFULL — RXFIFO full event. This interrupt is set if an RX FIFO is full.
    0=INT_EVENT0_ICLR_SRXFIFOFULL_NO_EFFECT (NO_EFFECT); 1=INT_EVENT0_ICLR_SRXFIFOFULL_CLR (CLR)
  [19] INT_EVENT0_ICLR_STXFIFOTRG — Slave Transmit FIFO Trigger
    0=INT_EVENT0_ICLR_STXFIFOTRG_NO_EFFECT (NO_EFFECT); 1=INT_EVENT0_ICLR_STXFIFOTRG_CLR (CLR)
  [18] INT_EVENT0_ICLR_SRXFIFOTRG — Slave Receive FIFO Trigger
    0=INT_EVENT0_ICLR_SRXFIFOTRG_NO_EFFECT (NO_EFFECT); 1=INT_EVENT0_ICLR_SRXFIFOTRG_CLR (CLR)
  [17] INT_EVENT0_ICLR_STXDONE — Slave Transmit Transaction completed Interrupt
    0=INT_EVENT0_ICLR_STXDONE_NO_EFFECT (NO_EFFECT); 1=INT_EVENT0_ICLR_STXDONE_CLR (CLR)
  [16] INT_EVENT0_ICLR_SRXDONE — Slave Receive Data Interrupt Signals that a byte has been received
    0=INT_EVENT0_ICLR_SRXDONE_NO_EFFECT (NO_EFFECT); 1=INT_EVENT0_ICLR_SRXDONE_CLR (CLR)
  [15] INT_EVENT0_ICLR_TIMEOUTB — Timeout B Interrupt
    0=INT_EVENT0_ICLR_TIMEOUTB_NO_EFFECT (NO_EFFECT); 1=INT_EVENT0_ICLR_TIMEOUTB_CLR (CLR)
  [14] INT_EVENT0_ICLR_TIMEOUTA — Timeout A interrupt
    0=INT_EVENT0_ICLR_TIMEOUTA_NO_EFFECT (NO_EFFECT); 1=INT_EVENT0_ICLR_TIMEOUTA_CLR (CLR)
  [13] INT_EVENT0_ICLR_MPEC_RX_ERR — Master RX Pec Error Interrupt
    0=INT_EVENT0_ICLR_MPEC_RX_ERR_NO_EFFECT (NO_EFFECT); 1=INT_EVENT0_ICLR_MPEC_RX_ERR_CLR (CLR)
  [12] INT_EVENT0_ICLR_MDMA_DONE1_3 — DMA Done 1 on Event Channel 3
    0=INT_EVENT0_ICLR_MDMA_DONE1_3_NO_EFFECT (NO_EFFECT); 1=INT_EVENT0_ICLR_MDMA_DONE1_3_CLR (CLR)
  [11] INT_EVENT0_ICLR_MDMA_DONE1_2 — DMA Done 1 on Event Channel 2
    0=INT_EVENT0_ICLR_MDMA_DONE1_2_NO_EFFECT (NO_EFFECT); 1=INT_EVENT0_ICLR_MDMA_DONE1_2_CLR (CLR)
  [10] INT_EVENT0_ICLR_MARBLOST — Arbitration Lost Interrupt
    0=INT_EVENT0_ICLR_MARBLOST_NO_EFFECT (NO_EFFECT); 1=INT_EVENT0_ICLR_MARBLOST_CLR (CLR)
  [9] INT_EVENT0_ICLR_MSTOP — STOP Detection Interrupt
    0=INT_EVENT0_ICLR_MSTOP_NO_EFFECT (NO_EFFECT); 1=INT_EVENT0_ICLR_MSTOP_CLR (CLR)
  [8] INT_EVENT0_ICLR_MSTART — START Detection Interrupt
    0=INT_EVENT0_ICLR_MSTART_NO_EFFECT (NO_EFFECT); 1=INT_EVENT0_ICLR_MSTART_CLR (CLR)
  [7] INT_EVENT0_ICLR_MNACK — Address/Data NACK Interrupt
    0=INT_EVENT0_ICLR_MNACK_NO_EFFECT (NO_EFFECT); 1=INT_EVENT0_ICLR_MNACK_CLR (CLR)
  [5] INT_EVENT0_ICLR_MTXEMPTY — Transmit FIFO Empty interrupt mask. This interrupt is set if all data in the Transmit FIFO have been shifted out and the transmit goes into idle mode.
    0=INT_EVENT0_ICLR_MTXEMPTY_NO_EFFECT (NO_EFFECT); 1=INT_EVENT0_ICLR_MTXEMPTY_CLR (CLR)
  [4] INT_EVENT0_ICLR_MRXFIFOFULL — RXFIFO full event.
    0=INT_EVENT0_ICLR_MRXFIFOFULL_NO_EFFECT (NO_EFFECT); 1=INT_EVENT0_ICLR_MRXFIFOFULL_CLR (CLR)
  [3] INT_EVENT0_ICLR_MTXFIFOTRG — Master Transmit FIFO Trigger Trigger when Transmit FIFO contains <= defined bytes
    0=INT_EVENT0_ICLR_MTXFIFOTRG_NO_EFFECT (NO_EFFECT); 1=INT_EVENT0_ICLR_MTXFIFOTRG_CLR (CLR)
  [2] INT_EVENT0_ICLR_MRXFIFOTRG — Master Receive FIFO Trigger Trigger when RX FIFO contains >= defined bytes
    0=INT_EVENT0_ICLR_MRXFIFOTRG_NO_EFFECT (NO_EFFECT); 1=INT_EVENT0_ICLR_MRXFIFOTRG_CLR (CLR)
  [1] INT_EVENT0_ICLR_MTXDONE — Master Transmit Transaction completed Interrupt
    0=INT_EVENT0_ICLR_MTXDONE_NO_EFFECT (NO_EFFECT); 1=INT_EVENT0_ICLR_MTXDONE_CLR (CLR)
  [0] INT_EVENT0_ICLR_MRXDONE — Master Receive Data Interrupt Signals that a byte has been received
    0=INT_EVENT0_ICLR_MRXDONE_NO_EFFECT (NO_EFFECT); 1=INT_EVENT0_ICLR_MRXDONE_CLR (CLR)
0x1050 INT_EVENT1_IIDX ro — Interrupt index
  [7:0] INT_EVENT1_IIDX_STAT — I2C Module Interrupt Vector Value. This register provides the highes priority interrupt index. A read clears the corresponding interrupt flag in RIS and MISC. 15h-1Fh = Reserved
    0=INT_EVENT1_IIDX_STAT_NO_INTR (NO_INTR); 1=INT_EVENT1_IIDX_STAT_MRXFIFOTRG (MRXFIFOTRG); 2=INT_EVENT1_IIDX_STAT_MTXFIFOTRG (MTXFIFOTRG); 3=INT_EVENT1_IIDX_STAT_SRXFIFOTRG (SRXFIFOTRG); 4=INT_EVENT1_IIDX_STAT_STXFIFOTRG (STXFIFOTRG)
0x1058 INT_EVENT1_IMASK — Interrupt mask
  [3] INT_EVENT1_IMASK_STXFIFOTRG — Slave Transmit FIFO Trigger
    0=INT_EVENT1_IMASK_STXFIFOTRG_CLR (CLR); 1=INT_EVENT1_IMASK_STXFIFOTRG_SET (SET)
  [2] INT_EVENT1_IMASK_SRXFIFOTRG — Slave Receive FIFO Trigger
    0=INT_EVENT1_IMASK_SRXFIFOTRG_CLR (CLR); 1=INT_EVENT1_IMASK_SRXFIFOTRG_SET (SET)
  [1] INT_EVENT1_IMASK_MTXFIFOTRG — Master Transmit FIFO Trigger Trigger when Transmit FIFO contains <= defined bytes
    0=INT_EVENT1_IMASK_MTXFIFOTRG_CLR (CLR); 1=INT_EVENT1_IMASK_MTXFIFOTRG_SET (SET)
  [0] INT_EVENT1_IMASK_MRXFIFOTRG — Master Receive FIFO Trigger Trigger when RX FIFO contains >= defined bytes
    0=INT_EVENT1_IMASK_MRXFIFOTRG_CLR (CLR); 1=INT_EVENT1_IMASK_MRXFIFOTRG_SET (SET)

## Notices in the file
Copyright (C) 2023 Texas Instruments Incorporated - http://www.ti.com
Redistribution and use in source and binary forms, with or without
modification, are permitted provided that the following conditions
are met:
Redistributions of source code must retain the above copyright
notice, this list of conditions and the following disclaimer.
Redistributions in binary form must reproduce the above copyright
notice, this list of conditions and the following disclaimer in the
documentation and/or other materials provided with the
distribution.
Neither the name of Texas Instruments Incorporated nor the names of
its contributors may be used to endorse or promote products derived
from this software without specific prior written permission.
THIS SOFTWARE IS PROVIDED BY THE COPYRIGHT HOLDERS AND CONTRIBUTORS
"AS IS" AND ANY EXPRESS OR IMPLIED WARRANTIES, INCLUDING, BUT NOT
LIMITED TO, THE IMPLIED WARRANTIES OF MERCHANTABILITY AND FITNESS FOR
A PARTICULAR PURPOSE ARE DISCLAIMED. IN NO EVENT SHALL THE COPYRIGHT
OWNER OR CONTRIBUTORS BE LIABLE FOR ANY DIRECT, INDIRECT, INCIDENTAL,
SPECIAL, EXEMPLARY, OR CONSEQUENTIAL DAMAGES (INCLUDING, BUT NOT
LIMITED TO, PROCUREMENT OF SUBSTITUTE GOODS OR SERVICES; LOSS OF USE,
DATA, OR PROFITS; OR BUSINESS INTERRUPTION) HOWEVER CAUSED AND ON ANY
THEORY OF LIABILITY, WHETHER IN CONTRACT, STRICT LIABILITY, OR TORT
(INCLUDING NEGLIGENCE OR OTHERWISE) ARISING IN ANY WAY OUT OF THE USE
OF THIS SOFTWARE, EVEN IF ADVISED OF THE POSSIBILITY OF SUCH DAMAGE.
